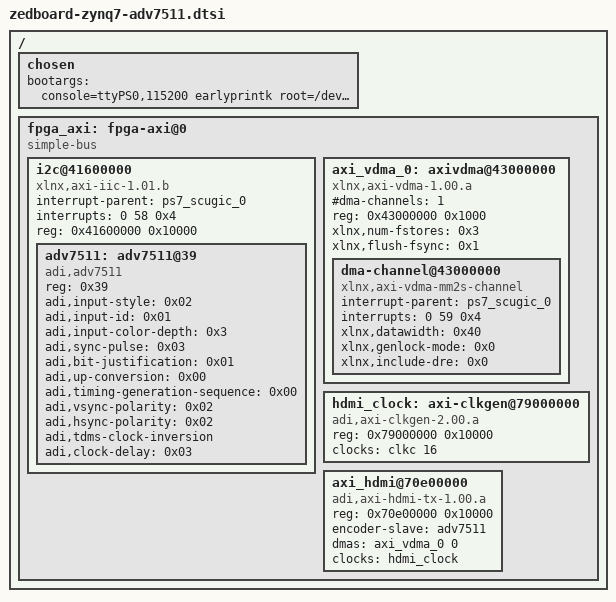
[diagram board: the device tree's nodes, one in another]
/ {
	chosen {
		bootargs = "console=ttyPS0,115200 earlyprintk root=/dev/ram rw";
	} ;
	fpga_axi: fpga-axi@0 {
		compatible = "simple-bus";
		#address-cells = <0x1>;
		#size-cells = <0x1>;
		ranges;

		i2c@41600000 {
			compatible = "xlnx,axi-iic-1.01.b", "xlnx,xps-iic-2.00.a";
			interrupt-parent = <&ps7_scugic_0>;
			interrupts = <0 58 0x4>;
			reg = <0x41600000 0x10000>;

			#size-cells = <0>;
			#address-cells = <1>;

			adv7511: adv7511@39 {
				compatible = "adi,adv7511";
				reg = <0x39>;

				adi,input-style = <0x02>;
				adi,input-id = <0x01>;
				adi,input-color-depth = <0x3>;
				adi,sync-pulse = <0x03>;
				adi,bit-justification = <0x01>;
				adi,up-conversion = <0x00>;
				adi,timing-generation-sequence = <0x00>;
				adi,vsync-polarity = <0x02>;
				adi,hsync-polarity = <0x02>;
				adi,tdms-clock-inversion;
				adi,clock-delay = <0x03>;
			};
		};

		axi_vdma_0: axivdma@43000000 {
			compatible = "xlnx,axi-vdma-1.00.a";
			#address-cells = <1>;
			#size-cells = <1>;
			#dma-cells = <1>;
			#dma-channels = <1>;
			reg = <0x43000000 0x1000>;
			xlnx,num-fstores = <0x3>;
                        xlnx,flush-fsync = <0x1>;
			dma-channel@43000000 {
				compatible = "xlnx,axi-vdma-mm2s-channel";
                                interrupt-parent = <&ps7_scugic_0>;
				interrupts = <0 59 0x4>;
				xlnx,datawidth = <0x40>;
				xlnx,genlock-mode = <0x0>;
				xlnx,include-dre = <0x0>;
			};
		};

                hdmi_clock: axi-clkgen@79000000 {
			compatible = "adi,axi-clkgen-2.00.a";
			reg = <0x79000000 0x10000>;
			#clock-cells = <0>;
			clocks = <&clkc 16>;
		};

		axi_hdmi@70e00000 {
			compatible = "adi,axi-hdmi-tx-1.00.a";
			reg = <0x70e00000 0x10000>;
			encoder-slave = <&adv7511>;
			dmas = <&axi_vdma_0 0>;
			dma-names = "video";
			clocks = <&hdmi_clock>;
		};
	};
};
